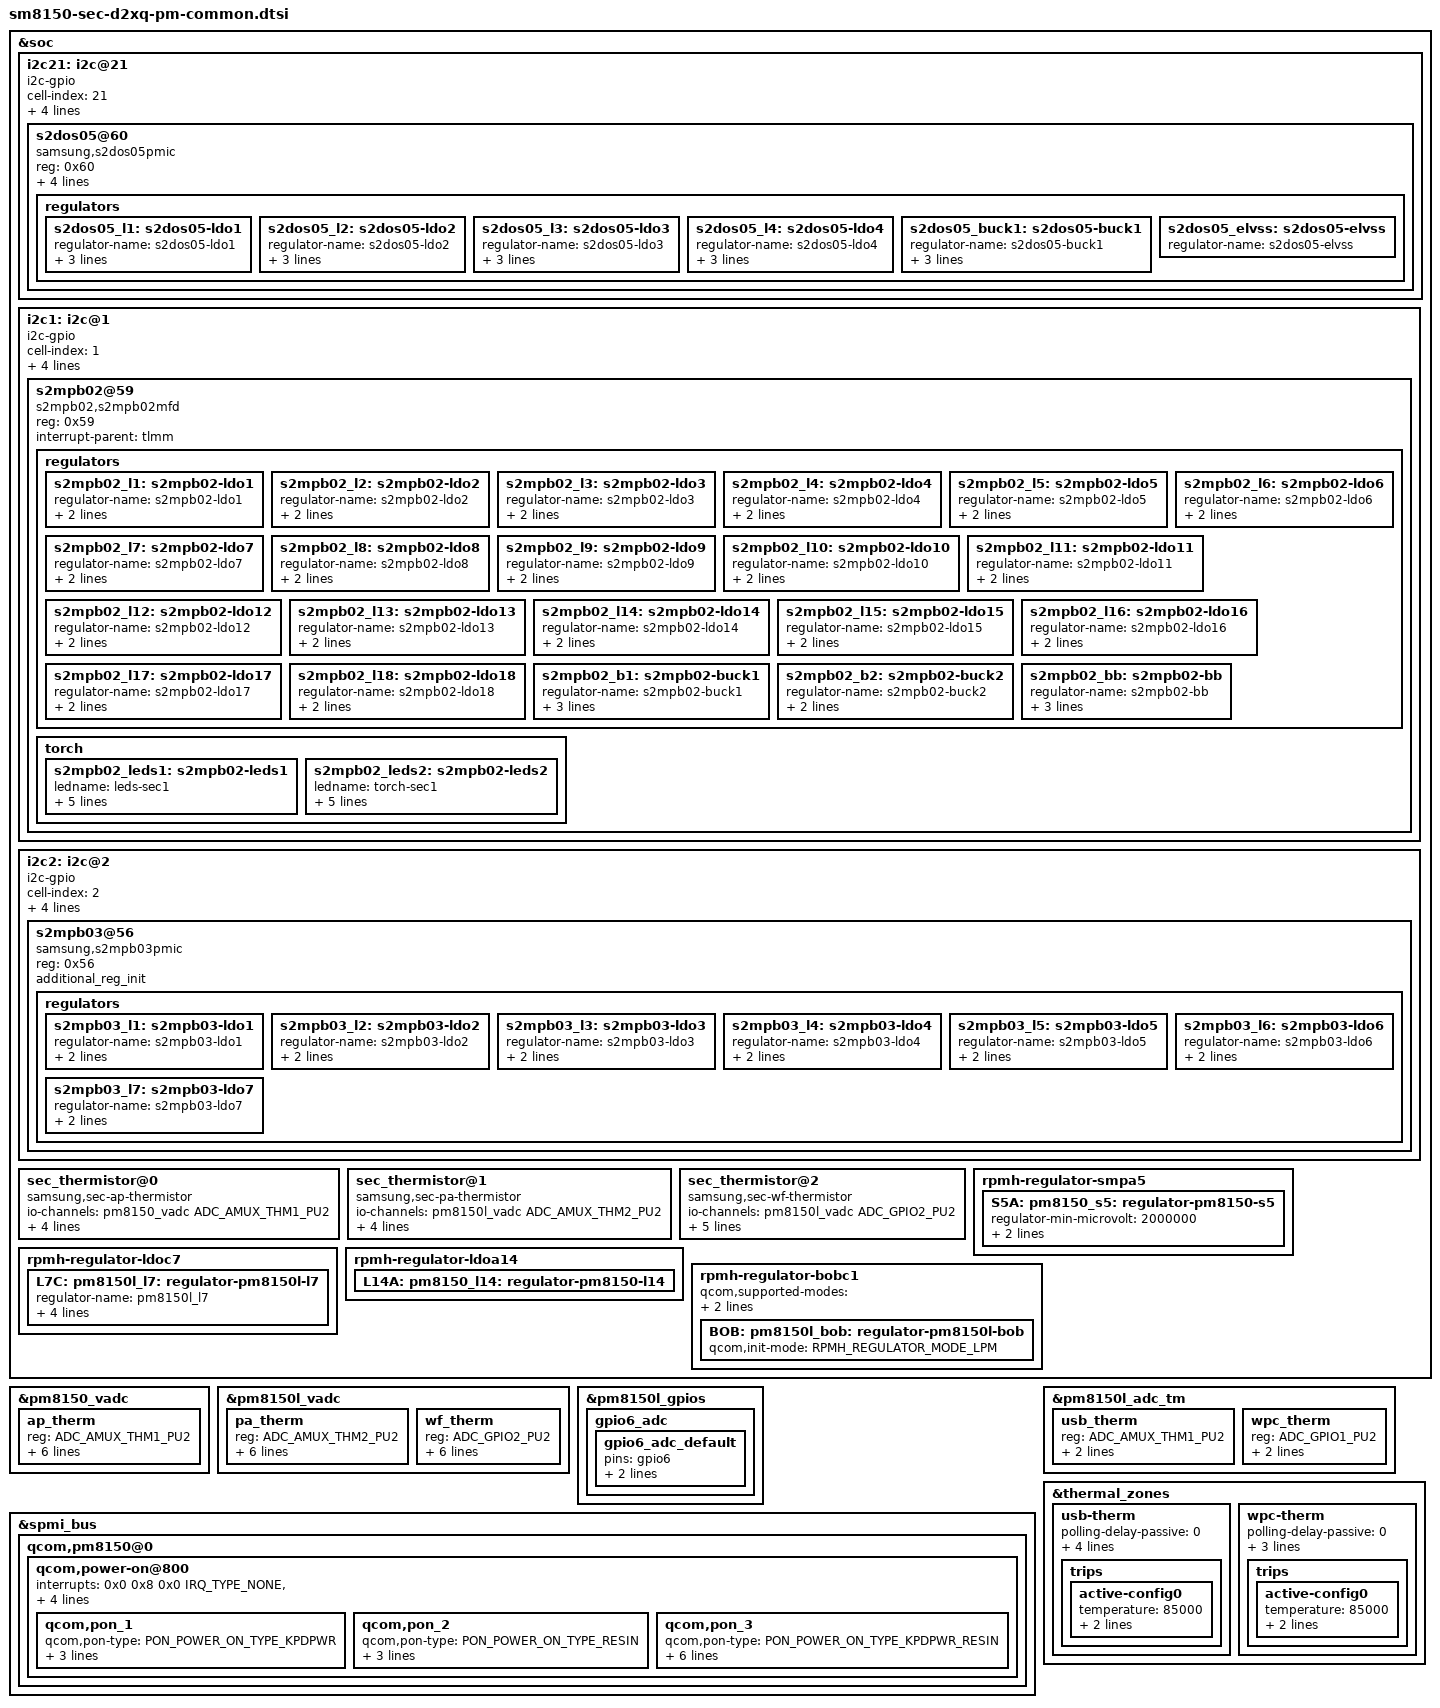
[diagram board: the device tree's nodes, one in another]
/* Copyright (c) 2014, The Linux Foundation. All rights reserved.
 *
 * This program is free software; you can redistribute it and/or modify
 * it under the terms of the GNU General Public License version 2 and
 * only version 2 as published by the Free Software Foundation.
 *
 * This program is distributed in the hope that it will be useful,
 * but WITHOUT ANY WARRANTY; without even the implied warranty of
 * MERCHANTABILITY or FITNESS FOR A PARTICULAR PURPOSE.  See the
 * GNU General Public License for more details.
 */

#include <dt-bindings/regulator/qcom,rpmh-regulator.h>

&soc {
	/* S2DOS05 Display PMIC */
	i2c21: i2c@21 {
		cell-index = <21>;
		compatible = "i2c-gpio";
		gpios = <&tlmm 153 0 /* sda */
			&tlmm 154 0 /* scl */
		>;
		#i2c-gpio,delay-us = <2>;
		#address-cells = <1>;
		#size-cells = <0>;

		pinctrl-names = "default";
		pinctrl-0 = <&s2dos05_i2c_sda_default &s2dos05_i2c_scl_default>;

		s2dos05@60 {
			compatible = "samsung,s2dos05pmic";
			reg = <0x60>;
			adc_mode = <2>; /* 0 : disable, 1 : current meter, 2 : power meter */
			adc_sync_mode = <2>; /* 1 : sync mode, 2 : async mode */

			pinctrl-names = "default";
			pinctrl-0 = <&s2dos05_irq_default>;
			s2dos05,s2dos05_int = <&tlmm 119 0>;

			regulators {
				s2dos05_l1: s2dos05-ldo1 {
					regulator-name = "s2dos05-ldo1";
					regulator-min-microvolt = <1500000>;
					regulator-max-microvolt = <2000000>;
					regulator-active-discharge = <1>;
				};

				s2dos05_l2: s2dos05-ldo2 {
					regulator-name = "s2dos05-ldo2";
					regulator-min-microvolt = <1500000>;
					regulator-max-microvolt = <2000000>;
					regulator-active-discharge = <1>;
				};

				s2dos05_l3: s2dos05-ldo3 {
					regulator-name = "s2dos05-ldo3";
					regulator-min-microvolt = <2700000>;
					regulator-max-microvolt = <3775000>;
					regulator-active-discharge = <1>;
				};

				s2dos05_l4: s2dos05-ldo4 {
					regulator-name = "s2dos05-ldo4";
					regulator-min-microvolt = <2700000>;
					regulator-max-microvolt = <3775000>;
					regulator-active-discharge = <1>;
				};

				s2dos05_buck1: s2dos05-buck1 {
					regulator-name = "s2dos05-buck1";
					regulator-min-microvolt = <850000>;
					regulator-max-microvolt = <2100000>;
					regulator-active-discharge = <1>;
				};

				s2dos05_elvss: s2dos05-elvss {
					regulator-name = "s2dos05-elvss";
				};
			};
		};
	};

	/* S2MPB02 Camera PMIC */
	i2c1: i2c@1 {
		cell-index = <1>;
		compatible = "i2c-gpio";
		gpios = <&tlmm 169 0
			&tlmm 170 0
		>;
		i2c-gpio,delay-us = <2>;
		#address-cells = <1>;
		#size-cells = <0>;

		pinctrl-names = "default";
		pinctrl-0 = <&s2mpb02_i2c_sda_default &s2mpb02_i2c_scl_default>;

		s2mpb02@59 {
			compatible = "s2mpb02,s2mpb02mfd";
			reg = <0x59>;

			interrupt-parent = <&tlmm>;
			status = "okay";

			regulators {
				s2mpb02_l1: s2mpb02-ldo1 {
					regulator-name = "s2mpb02-ldo1";
					regulator-min-microvolt = <1025000>;
					regulator-max-microvolt = <1200000>;
				};

				s2mpb02_l2: s2mpb02-ldo2 {
					regulator-name = "s2mpb02-ldo2";
					regulator-min-microvolt = <1000000>;
					regulator-max-microvolt = <1200000>;
				};

				s2mpb02_l3: s2mpb02-ldo3 {
					regulator-name = "s2mpb02-ldo3";
					regulator-min-microvolt = <1025000>;
					regulator-max-microvolt = <1200000>;
				};

				s2mpb02_l4: s2mpb02-ldo4 {
					regulator-name = "s2mpb02-ldo4";
					regulator-min-microvolt = <1050000>;
					regulator-max-microvolt = <1050000>;
				};

				s2mpb02_l5: s2mpb02-ldo5 {
					regulator-name = "s2mpb02-ldo5";
					regulator-min-microvolt = <1050000>;
					regulator-max-microvolt = <1050000>;
				};

				s2mpb02_l6: s2mpb02-ldo6 {
					regulator-name = "s2mpb02-ldo6";
					regulator-min-microvolt = <1800000>;
					regulator-max-microvolt = <1800000>;
				};

				s2mpb02_l7: s2mpb02-ldo7 {
					regulator-name = "s2mpb02-ldo7";
					regulator-min-microvolt = <1800000>;
					regulator-max-microvolt = <1800000>;
				};

				s2mpb02_l8: s2mpb02-ldo8 {
					regulator-name = "s2mpb02-ldo8";
					regulator-min-microvolt = <1800000>;
					regulator-max-microvolt = <1800000>;
				};

				s2mpb02_l9: s2mpb02-ldo9 {
					regulator-name = "s2mpb02-ldo9";
					regulator-min-microvolt = <1800000>;
					regulator-max-microvolt = <1800000>;
				};

				s2mpb02_l10: s2mpb02-ldo10 {
					regulator-name = "s2mpb02-ldo10";
					regulator-min-microvolt = <1800000>;
					regulator-max-microvolt = <1800000>;
				};

				s2mpb02_l11: s2mpb02-ldo11 {
					regulator-name = "s2mpb02-ldo11";
					regulator-min-microvolt = <2800000>;
					regulator-max-microvolt = <2800000>;
				};

				s2mpb02_l12: s2mpb02-ldo12 {
					regulator-name = "s2mpb02-ldo12";
					regulator-min-microvolt = <2800000>;
					regulator-max-microvolt = <2800000>;
				};

				s2mpb02_l13: s2mpb02-ldo13 {
					regulator-name = "s2mpb02-ldo13";
					regulator-min-microvolt = <2800000>;
					regulator-max-microvolt = <3300000>;
				};

				s2mpb02_l14: s2mpb02-ldo14 {
					regulator-name = "s2mpb02-ldo14";
					regulator-min-microvolt = <3300000>;
					regulator-max-microvolt = <3300000>;
				};

				s2mpb02_l15: s2mpb02-ldo15 {
					regulator-name = "s2mpb02-ldo15";
					regulator-min-microvolt = <2800000>;
					regulator-max-microvolt = <2800000>;
				};

				s2mpb02_l16: s2mpb02-ldo16 {
					regulator-name = "s2mpb02-ldo16";
					regulator-min-microvolt = <2800000>;
					regulator-max-microvolt = <2800000>;
				};

				s2mpb02_l17: s2mpb02-ldo17 {
					regulator-name = "s2mpb02-ldo17";
					regulator-min-microvolt = <2700000>;
					regulator-max-microvolt = <2800000>;
				};

				s2mpb02_l18: s2mpb02-ldo18 {
					regulator-name = "s2mpb02-ldo18";
					regulator-min-microvolt = <3400000>;
					regulator-max-microvolt = <3400000>;
				};

				s2mpb02_b1: s2mpb02-buck1 {
					regulator-name = "s2mpb02-buck1";
					regulator-min-microvolt = <1300000>;
					regulator-max-microvolt = <1300000>;
					regulator-always-on;
				};

				s2mpb02_b2: s2mpb02-buck2 {
					regulator-name = "s2mpb02-buck2";
					regulator-min-microvolt = <1300000>;
					regulator-max-microvolt = <1300000>;
				};

				s2mpb02_bb: s2mpb02-bb {
					regulator-name = "s2mpb02-bb";
					regulator-min-microvolt = <3500000>;
					regulator-max-microvolt = <3500000>;
					regulator-always-on;
				};
			};

			torch {
				status = "okay";
				s2mpb02_leds1: s2mpb02-leds1 {
					ledname = "leds-sec1";
					/* S2MPB02_FLASH_LED_1 */
					id = <0>;
					/* S2MPB02_FLASH_CURRENT */
					brightness = <0xA>;
					/* S2MPB02_FLASH_TIMEOUT */
					timeout = <0x7>;
					default-trigger = "flash_trigger";
					gpios = <&tlmm 171 0>;
				};

				s2mpb02_leds2: s2mpb02-leds2 {
					ledname = "torch-sec1";
					/* S2MPB02_TORCH_LED_1 */
					id = <1>;
					/* S2MPB02_TORCH_CURRENT */
					brightness = <0x9>;
					/* S2MPB02_TORCH_TIMEOUT */
					timeout = <0xF>;
					default-trigger = "torch_trigger";
					gpios = <&tlmm 174 0>;
				};
			};
		};
	};

	/* S2MPB03 Camera PMIC */
	i2c2: i2c@2 {
		cell-index = <2>;
		compatible = "i2c-gpio";
		gpios = <&tlmm 172 0 /* sda */
			&tlmm 173 0 /* scl */
		>;
		#i2c-gpio,delay-us = <2>;
		#address-cells = <1>;
		#size-cells = <0>;

		pinctrl-names = "default";
		pinctrl-0 = <&s2mpb03_i2c_sda_default &s2mpb03_i2c_scl_default>;

		/* S2MPB03 Camera PMIC */
		s2mpb03@56 {
			compatible = "samsung,s2mpb03pmic";
			reg = <0x56>;
			additional_reg_init;

			regulators {
				s2mpb03_l1: s2mpb03-ldo1 {
					regulator-name = "s2mpb03-ldo1";
					regulator-min-microvolt = <1025000>;
					regulator-max-microvolt = <1025000>;
				};

				s2mpb03_l2: s2mpb03-ldo2 {
					regulator-name = "s2mpb03-ldo2";
					regulator-min-microvolt = <1100000>;
					regulator-max-microvolt = <1100000>;
				};

				s2mpb03_l3: s2mpb03-ldo3 {
					regulator-name = "s2mpb03-ldo3";
					regulator-min-microvolt = <1800000>;
					regulator-max-microvolt = <1800000>;
				};

				s2mpb03_l4: s2mpb03-ldo4 {
					regulator-name = "s2mpb03-ldo4";
					regulator-min-microvolt = <700000>;
					regulator-max-microvolt = <1025000>;
				};

				s2mpb03_l5: s2mpb03-ldo5 {
					regulator-name = "s2mpb03-ldo5";
					regulator-min-microvolt = <2400000>;
					regulator-max-microvolt = <2400000>;
				};

				s2mpb03_l6: s2mpb03-ldo6 {
					regulator-name = "s2mpb03-ldo6";
					regulator-min-microvolt = <2800000>;
					regulator-max-microvolt = <2800000>;
				};

				s2mpb03_l7: s2mpb03-ldo7 {
					regulator-name = "s2mpb03-ldo7";
					regulator-min-microvolt = <2800000>;
					regulator-max-microvolt = <2800000>;
				};
			};
		};
	};

	/* AP Thermistor table */
	sec_thermistor@0 {
		compatible = "samsung,sec-ap-thermistor";
		status = "okay";
		io-channels = <&pm8150_vadc ADC_AMUX_THM1_PU2>;
		io-channel-names = "ap_therm";
		adc_array = <117560 122249 126937 131626 136314 141003 146773 152543 158313 164083
				169853 176981 184109 191237 198365 205493 212997 220501 228006 235510
				243014 252417 261820 271224 280627 290030 300255 310480 320704 330929
				341154 353269 365384 377500 389615 401730 415964 430199 444433 458668
				472902 488620 504338 520055 535773 551491 570012 588533 607054 625575
				644096 662703 681310 699918 718525 737132 757552 777971 798391 818810
				839230 861583 883936 906289 928642 950995 969758 988521 1007283 1026046
				1044809 1067768 1090726 1113685 1136643 1159602 1180493 1201384 1222275 1243166
				1264057 1283118 1302180 1321241 1340303 1359364 1373603 1387842 1402080 1416319
				1430558
				1448054 1465549 1483045 1500540 1518036 1532054 1546072 1560091 1574109 1588127
				1601211 1614295 1627378 1640462 1653546 1663646 1673745 1683845 1693944 1704044>;

		temp_array = <900 890 880 870 860 850 840 830 820 810
				800 790 780 770 760 750 740 730 720 710
				700 690 680 670 660 650 640 630 620 610
				600 590 580 570 560 550 540 530 520 510
				500 490 480 470 460 450 440 430 420 410
				400 390 380 370 360 350 340 330 320 310
				300 290 280 270 260 250 240 230 220 210
				200 190 180 170 160 150 140 130 120 110
				100 90 80 70 60 50 40 30 20 10
				0
				(-10) (-20) (-30) (-40) (-50) (-60) (-70) (-80) (-90) (-100)
				(-110)(-120)(-130)(-140)(-150)(-160)(-170)(-180)(-190) (-200)>;
	};

	/* PA Thermistor table */
	sec_thermistor@1 {
		compatible = "samsung,sec-pa-thermistor";
		status = "okay";
		io-channels = <&pm8150l_vadc ADC_AMUX_THM2_PU2>;
		io-channel-names = "pa_therm";
		adc_array = <122685 127382 132080 136777 141475 146172 151933 157694 163456 169217
				174978 182180 189381 196583 203784 210986 218590 226194 233797 241401
				249005 258464 267923 277383 286842 296301 306604 316907 327209 337512
				347815 359986 372158 384329 396501 408672 423023 437374 451726 466077
				480428 496206 511985 527763 543542 559320 577914 596509 615103 633698
				652292 670925 689558 708192 726825 745458 765908 786358 806807 827257
				847707 870051 892396 914740 937085 959429 979645 999861 1020078 1040294
				1060510 1083244 1105977 1128711 1151444 1174178 1194861 1215545 1236228 1256912
				1277595 1296501 1315406 1334312 1353217 1372123 1386215 1400307 1414398 1428490
				1442582
				1459230 1475878 1492525 1509173 1525821 1539887 1553953 1568018 1582084 1596150
				1608996 1621842 1634688 1647534 1660380 1670151 1679922 1689692 1699463 1709234>;

		temp_array = <900 890 880 870 860 850 840 830 820 810
				800 790 780 770 760 750 740 730 720 710
				700 690 680 670 660 650 640 630 620 610
				600 590 580 570 560 550 540 530 520 510
				500 490 480 470 460 450 440 430 420 410
				400 390 380 370 360 350 340 330 320 310
				300 290 280 270 260 250 240 230 220 210
				200 190 180 170 160 150 140 130 120 110
				100 90 80 70 60 50 40 30 20 10
				0
				(-10) (-20) (-30) (-40) (-50) (-60) (-70) (-80) (-90) (-100)
				(-110)(-120)(-130)(-140)(-150)(-160)(-170)(-180)(-190) (-200)>;
	};

	/* WiFi Thermistor table */
	sec_thermistor@2 {
		compatible = "samsung,sec-wf-thermistor";
		status = "okay";
		io-channels = <&pm8150l_vadc ADC_GPIO2_PU2>;
		io-channel-names = "wf_therm";
		pinctrl-names = "default";
		pinctrl-0 = <&gpio6_adc_default>;
		adc_array = <117560 122249 126937 131626 136314 141003 146773 152543 158313 164083
				169853 176981 184109 191237 198365 205493 212997 220501 228006 235510
				243014 252417 261820 271224 280627 290030 300255 310480 320704 330929
				341154 353269 365384 377500 389615 401730 415964 430199 444433 458668
				472902 488620 504338 520055 535773 551491 570012 588533 607054 625575
				644096 662703 681310 699918 718525 737132 757552 777971 798391 818810
				839230 861583 883936 906289 928642 950995 969758 988521 1007283 1026046
				1044809 1067768 1090726 1113685 1136643 1159602 1180493 1201384 1222275 1243166
				1264057 1283118 1302180 1321241 1340303 1359364 1373603 1387842 1402080 1416319
				1430558
				1448054 1465549 1483045 1500540 1518036 1532054 1546072 1560091 1574109 1588127
				1601211 1614295 1627378 1640462 1653546 1663646 1673745 1683845 1693944 1704044>;

		temp_array = <900 890 880 870 860 850 840 830 820 810
				800 790 780 770 760 750 740 730 720 710
				700 690 680 670 660 650 640 630 620 610
				600 590 580 570 560 550 540 530 520 510
				500 490 480 470 460 450 440 430 420 410
				400 390 380 370 360 350 340 330 320 310
				300 290 280 270 260 250 240 230 220 210
				200 190 180 170 160 150 140 130 120 110
				100 90 80 70 60 50 40 30 20 10
				0
				(-10) (-20) (-30) (-40) (-50) (-60) (-70) (-80) (-90) (-100)
				(-110)(-120)(-130)(-140)(-150)(-160)(-170)(-180)(-190) (-200)>;
	};

	rpmh-regulator-smpa5 {
		S5A: pm8150_s5: regulator-pm8150-s5 {
			regulator-min-microvolt = <2000000>;
			regulator-max-microvolt = <2000000>;
			qcom,init-voltage = <2000000>;
		};
	};

	/* H/W request */
	rpmh-regulator-ldoc7 {
		L7C: pm8150l_l7: regulator-pm8150l-l7 {
			regulator-name = "pm8150l_l7";
			regulator-min-microvolt = <2050000>;
			regulator-max-microvolt = <2050000>;
			qcom,init-voltage = <2050000>;
			regulator-always-on;
		};
	};

	rpmh-regulator-ldoa14 {
		L14A: pm8150_l14: regulator-pm8150-l14 {
			/delete-property/ qcom,proxy-consumer-enable;
			/delete-property/ qcom,proxy-consumer-current;
		};
	};

	/* H/W request */
	rpmh-regulator-bobc1 {
		qcom,supported-modes =
			<RPMH_REGULATOR_MODE_LPM
			 RPMH_REGULATOR_MODE_HPM>;
		qcom,mode-threshold-currents = <0 2000000>;

		BOB: pm8150l_bob: regulator-pm8150l-bob {
			qcom,init-mode = <RPMH_REGULATOR_MODE_LPM>;
		};
	};
};

&pm8150_vadc {
	/delete-node/ skin_therm;
	ap_therm {
		reg = <ADC_AMUX_THM1_PU2>;
		label = "ap_therm";
		qcom,ratiometric;
		qcom,hw-settle-time = <200>;
		qcom,pre-scaling = <1 1>;
		qcom,decimation = <840>;
		qcom,avg-samples = <8>;
	};
};

&pm8150l_vadc {
	/delete-node/ skin_msm_therm;
	pa_therm {
		reg = <ADC_AMUX_THM2_PU2>;
		label = "pa_therm";
		qcom,ratiometric;
		qcom,hw-settle-time = <200>;
		qcom,pre-scaling = <1 1>;
		qcom,decimation = <840>;
		qcom,avg-samples = <8>;
	};

	wf_therm {
		reg = <ADC_GPIO2_PU2>;
		label = "wf_therm";
		qcom,ratiometric;
		qcom,hw-settle-time = <200>;
		qcom,pre-scaling = <1 1>;
		qcom,decimation = <840>;
		qcom,avg-samples = <8>;
	};
};

&pm8150l_gpios {
	gpio6_adc {
		gpio6_adc_default: gpio6_adc_default {
			pins = "gpio6";
			function = "normal";
			bias-high-impedance;
		};
	};
};

&spmi_bus {
	qcom,pm8150@0 {
		qcom,power-on@800 {
			interrupts = <0x0 0x8 0x0 IRQ_TYPE_NONE>,
				     <0x0 0x8 0x1 IRQ_TYPE_NONE>,
					 <0x0 0x8 0x4 IRQ_TYPE_NONE>,
				     <0x0 0x8 0x5 IRQ_TYPE_NONE>;
			interrupt-names = "kpdpwr", "resin",
                    "resin-bark", "kpdpwr-resin-bark";

			qcom,s3-debounce = <128>;
			qcom,pon_1 {
				qcom,pon-type = <PON_POWER_ON_TYPE_KPDPWR>;
				qcom,support-reset = <0>;
				qcom,pull-up = <1>;
				linux,code = <KEY_POWER>;
			};

			qcom,pon_2 {
				qcom,pon-type = <PON_POWER_ON_TYPE_RESIN>;
				qcom,support-reset = <0>;
				qcom,pull-up = <1>;
				linux,code = <KEY_VOLUMEDOWN>;
			};

			qcom,pon_3 {
				qcom,pon-type = <PON_POWER_ON_TYPE_KPDPWR_RESIN>;
				qcom,support-reset = <1>;
				qcom,pull-up = <1>;
				qcom,s1-timer = <6720>;
				qcom,s2-timer = <1000>;
				qcom,s2-type = <8>;
				qcom,use-bark;
			};
		};
	};
};

&pm8150l_adc_tm {
	usb_therm {
		reg = <ADC_AMUX_THM1_PU2>;
		qcom,ratiometric;
		qcom,hw-settle-time = <200>;
	};

	wpc_therm {
		reg = <ADC_GPIO1_PU2>;
		qcom,ratiometric;
		qcom,hw-settle-time = <200>;
	};
};

&thermal_zones {
	 usb-therm {
		polling-delay-passive = <0>;
		polling-delay = <0>;
		thermal-governor = "user_space";
		thermal-sensors = <&pm8150l_adc_tm ADC_AMUX_THM1_PU2>;
		trips {
			active-config0 {
				temperature = <85000>;
				hysteresis = <15000>;
				type = "passive";
			};
		};
	};

	wpc-therm {
		polling-delay-passive = <0>;
		polling-delay = <0>;
		thermal-governor = "user_space";
		thermal-sensors = <&pm8150l_adc_tm ADC_GPIO1_PU2>;
		trips {
			active-config0 {
				temperature = <85000>;
				hysteresis = <15000>;
				type = "passive";
			};
		};
	};
};
